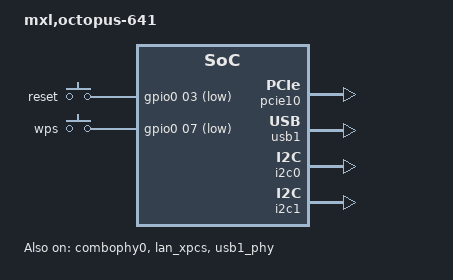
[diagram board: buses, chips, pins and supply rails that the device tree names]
// SPDX-License-Identifier: GPL-2.0
/*
 * Copyright (C) 2023-2024 MaxLinear, Inc.
 */
#include <dt-bindings/input/input.h>
#include "octopus_641.dtsi"

/******************************************************************************
** Board configuration: Enable buttons on the board.
******************************************************************************/
/ {
	gpio-keys-polled {
		compatible = "gpio-keys-polled";
		#address-cells = <1>;
		#size-cells = <0>;
		poll-interval = <100>;

		reset {
			label = "reset";
			gpios = <&gpio0 03 1>;
			linux,code = <KEY_RESTART>;
		};
		wps {
			label = "wps";
			gpios = <&gpio0 07 1>;
			linux,code = <KEY_WPS_BUTTON>;
		};
	};
};

/ {
	model = "mxl,octopus-641";

	chosen {
		/* ramfs */
		bootargs = "earlycon console=ttyLTQ0,115200n8r root=/dev/ram init=/init maxcpus=2 initcall_debug=0 clk_ignore_unused loglevel=8";
		stdout-path = "serial0";
	};
};


/* combo PHY setting */
/* combo phy 0 */
&combophy0 { /* PCIe10/11, HSIOL_XPCS0/1, SATA10/11 */ 
	status = "okay";
};

/* Enable P34x */
&lan_xpcs {
	status = "okay";
};

/* PCIe */
&pcie10 {
	status = "okay";
};

&usb1_phy {
	status = "okay";
	vbus-supply = <&usb_vbus>;
};

&usb1 {
	status = "okay";
};

&i2c0 { /* used by PMIC */
	status = "okay";
};

&i2c1 { /* used by USB type-C */
	status = "okay";
};

&gphy0 {
	mxl,usxgmii-reach = <0>; /* 0(short), 1(medium), 2(long) */
};

&gphy1 {
	mxl,usxgmii-reach = <0>; /* 0(short), 1(medium), 2(long) */
};

&gphy2 {
	mxl,usxgmii-reach = <0>; /* 0(short), 1(medium), 2(long) */
};

&gphy3 {
	mxl,usxgmii-reach = <0>; /* 0(short), 1(medium), 2(long) */
};
